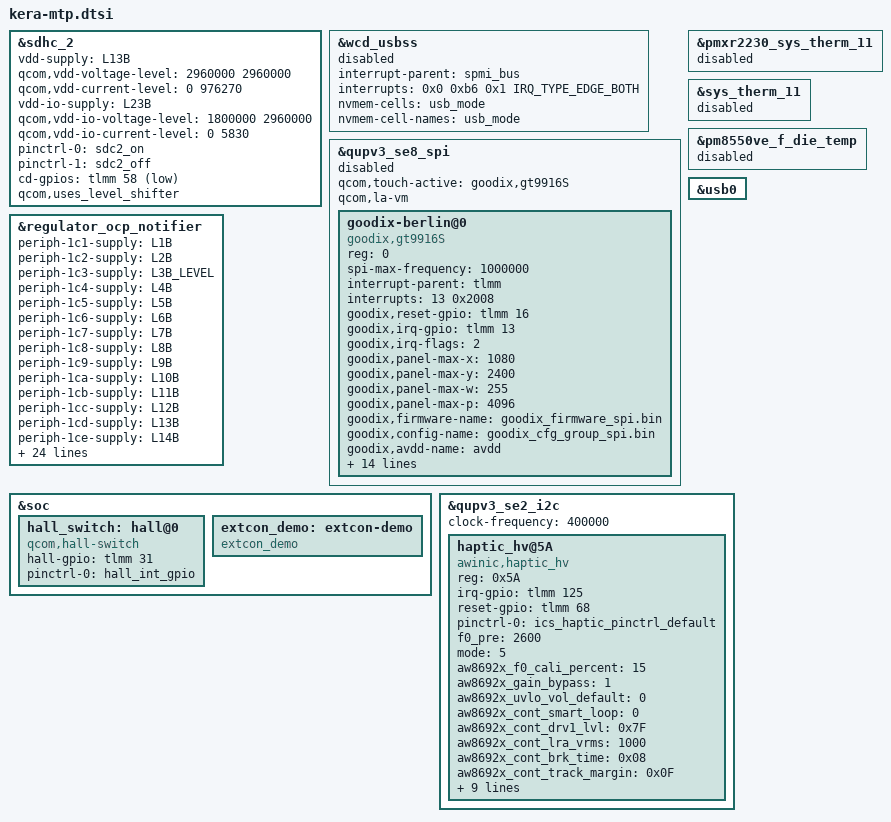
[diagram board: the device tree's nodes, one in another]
// SPDX-License-Identifier: BSD-3-Clause
/*
 * Copyright (c) 2024-2025 Qualcomm Innovation Center, Inc. All rights reserved.
 */
#include <dt-bindings/gpio/gpio.h>
#include <dt-bindings/input/input.h>
#include <dt-bindings/clock/qcom,gcc-kera.h>
#include <dt-bindings/interrupt-controller/irq.h>
#include <dt-bindings/spmi/spmi.h>

&sdhc_2 {
	vdd-supply = <&L13B>;
	qcom,vdd-voltage-level = <2960000 2960000>;
	qcom,vdd-current-level = <0 976270>;

	vdd-io-supply = <&L23B>;
	qcom,vdd-io-voltage-level = <1800000 2960000>;
	qcom,vdd-io-current-level = <0 5830>;

	pinctrl-names = "default", "sleep";
	pinctrl-0 = <&sdc2_on>;
	pinctrl-1 = <&sdc2_off>;

	cd-gpios = <&tlmm 58 GPIO_ACTIVE_LOW>;

	qcom,uses_level_shifter;

	status = "ok";
};

&wcd_usbss {
	interrupt-parent = <&spmi_bus>;
	interrupts = <0x0 0xb6 0x1 IRQ_TYPE_EDGE_BOTH>;
	interrupt-names = "usb_wcd";
	nvmem-cells = <&usb_mode>;
	nvmem-cell-names = "usb_mode";
	status = "disabled";
};

&qupv3_se8_spi {
	#address-cells = <1>;
	#size-cells = <0>;

	status = "disabled";
	qcom,touch-active = "goodix,gt9916S";
	qcom,la-vm;

	goodix-berlin@0 {
		compatible = "goodix,gt9916S";
		reg = <0>;
		spi-max-frequency = <1000000>;
		interrupt-parent = <&tlmm>;
		interrupts = <13 0x2008>;
		goodix,reset-gpio = <&tlmm 16 0x00>;
		goodix,irq-gpio = <&tlmm 13 0x2008>;
		goodix,irq-flags = <2>;
		goodix,panel-max-x = <1080>;
		goodix,panel-max-y = <2400>;
		goodix,panel-max-w = <255>;
		goodix,panel-max-p = <4096>;
		goodix,firmware-name = "goodix_firmware_spi.bin";
		goodix,config-name = "goodix_cfg_group_spi.bin";
		goodix,avdd-name = "avdd";
		goodix,iovdd-name = "iovdd";
		avdd-supply = <&L22B>;
		iovdd-supply = <&L8B>;
		goodix,touch-type = "primary";
		goodix,qts_en;

		qts,trusted-touch-mode = "vm_mode";
		qts,touch-environment = "pvm";
		qts,trusted-touch-type = "primary";
		qts,trusted-touch-spi-irq = <653>;
		qts,trusted-touch-io-bases = <0x880000>;
		qts,trusted-touch-io-sizes = <0x1000>;
		qts,trusted-touch-vm-gpio-list = <&tlmm 0 0 &tlmm 1 0 &tlmm 2 0
						&tlmm 3 0 &tlmm 16 0 &tlmm 13 0x2008>;
	};
};

&pmxr2230_sys_therm_11 {
	status = "disabled";
};

&sys_therm_11 {
	status = "disabled";
};

&pm8550ve_f_die_temp {
	status = "disabled";
};

&usb0 {
        //qcom,wcd_usbss = <&wcd_usbss>;
};

&regulator_ocp_notifier {
	periph-1c1-supply = <&L1B>;
	periph-1c2-supply = <&L2B>;
	periph-1c3-supply = <&L3B_LEVEL>;
	periph-1c4-supply = <&L4B>;
	periph-1c5-supply = <&L5B>;
	periph-1c6-supply = <&L6B>;
	periph-1c7-supply = <&L7B>;
	periph-1c8-supply = <&L8B>;
	periph-1c9-supply = <&L9B>;
	periph-1ca-supply = <&L10B>;
	periph-1cb-supply = <&L11B>;
	periph-1cc-supply = <&L12B>;
	periph-1cd-supply = <&L13B>;
	periph-1ce-supply = <&L14B>;
	periph-1cf-supply = <&L15B>;
	periph-1d0-supply = <&L16B>;
	periph-1d1-supply = <&L17B>;
	periph-1d2-supply = <&L18B>;
	periph-1d3-supply = <&L19B>;
	periph-1d4-supply = <&L20B>;
	periph-1d5-supply = <&L21B>;
	periph-1d6-supply = <&L22B>;
	periph-1d7-supply = <&L23B>;
	periph-19b-supply = <&S1B>;
	periph-19e-supply = <&S2B>;
	periph-1a1-supply = <&S3B>;
	periph-1a2-supply = <&S4B>;
	periph-1e4-supply = <&BOB>;
	periph-3c1-supply = <&L1D>;
	periph-3c2-supply = <&L2D>;
	periph-3c3-supply = <&L3D_LEVEL>;
	periph-39b-supply = <&S1D_LEVEL>;
	periph-3a1-supply = <&S3D_LEVEL>;
	periph-3a2-supply = <&S4D_LEVEL>;
	periph-3a3-supply = <&S5D_LEVEL>;
	periph-6c1-supply = <&L1G>;
	periph-6c2-supply = <&L2G>;
	periph-6c3-supply = <&L3G>;
};

&soc {
	hall_switch: hall@0 {
	    compatible = "qcom,hall-switch";
	    hall-gpio = <&tlmm 31 0>;
	    pinctrl-names = "default";
	    pinctrl-0 = <&hall_int_gpio>;
	};

	extcon_demo: extcon-demo {
		compatible = "extcon_demo";
		status = "okay";
	};
};

&qupv3_se2_i2c {
	clock-frequency = <400000>;
	status = "ok";
	haptic_hv@5A {
		compatible = "awinic,haptic_hv";
		reg = < 0x5A >;
		irq-gpio = < &tlmm 125 0 >;
		reset-gpio = < &tlmm 68 0 >;
		pinctrl-names = "default";
		pinctrl-0 = < &ics_haptic_pinctrl_default>;
		f0_pre = < 2600 >;
		mode = /bits/ 8 < 5 >;

		aw8692x_f0_cali_percent = /bits/ 8 < 15 >;
		aw8692x_gain_bypass = /bits/ 8 < 1 >;
		aw8692x_uvlo_vol_default = /bits/ 8 < 0 >;
		aw8692x_cont_smart_loop = /bits/ 8 < 0 >;
		aw8692x_cont_drv1_lvl = /bits/ 8 < 0x7F >;
		aw8692x_cont_lra_vrms = < 1000 >;
		aw8692x_cont_brk_time = /bits/ 8 < 0x08 >;
		aw8692x_cont_track_margin = /bits/ 8 < 0x0F >;
		aw8692x_cont_brk_gain = /bits/ 8 < 0x08 >;
		aw8692x_cont_drv1_time = /bits/ 8 < 0x04 >;
		aw8692x_cont_drv2_time = /bits/ 8 < 0x14 >;
		aw8692x_duration_time = /bits/ 8 < 20 30 60 >;
		aw8692x_d2s_gain = /bits/ 8 < 0x04 >;
		aw8692x_trig_config = /bits/ 8 < 0 0 0 1 0 2 0 0
						 0 0 0 1 0 2 0 0
						 0 0 0 1 0 2 0 0 >;
		aw8692x_bst_vol_default = < 8000 >;
		aw8692x_is_enabled_track_en;
		/* aw8692x_is_enabled_auto_bst; */
		/* aw8692x_is_enabled_one_wire; */
	};
};
